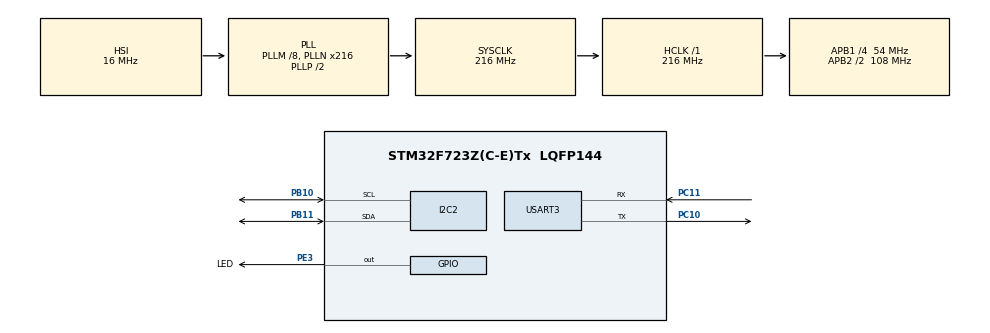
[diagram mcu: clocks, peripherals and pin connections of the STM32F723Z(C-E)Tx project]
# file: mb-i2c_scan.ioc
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FREERTOS.Tasks01=defaultTask,24,128,StartDefaultTask,Default,NULL,Dynamic,NULL,NULL;myTaskLED,8,128,StartTaskLED,Default,NULL,Dynamic,NULL,NULL
FREERTOS.configUSE_NEWLIB_REENTRANT=1
I2C2.Timing=0x20404768
Mcu.Family=STM32F7
Mcu.Name=STM32F723Z(C-E)Tx
Mcu.Package=LQFP144
NVIC.PriorityGroup=NVIC_PRIORITYGROUP_4
NVIC.TIM8_UP_TIM13_IRQn=true\:15\:0\:false\:false\:true\:false\:false\:true\:true
NVIC.TimeBase=TIM8_UP_TIM13_IRQn
NVIC.TimeBaseIP=TIM13
NVIC.USART3_IRQn=true\:5\:0\:false\:false\:true\:true\:true\:true\:true
PB10.Mode=I2C
PB10.Signal=I2C2_SCL
PB11.Mode=I2C
PB11.Signal=I2C2_SDA
PC10.Mode=Asynchronous
PC10.Signal=USART3_TX
PC11.Mode=Asynchronous
PC11.Signal=USART3_RX
PE3.GPIO_Label=LED
PE3.Signal=GPIO_Output
PH0-OSC_IN.Mode=HSE-External-Oscillator
PH0-OSC_IN.Signal=RCC_OSC_IN
PH1-OSC_OUT.Mode=HSE-External-Oscillator
PH1-OSC_OUT.Signal=RCC_OSC_OUT
ProjectManager.HeapSize=0x200
ProjectManager.StackSize=0x400
ProjectManager.TargetToolchain=STM32CubeIDE
RCC.AHBFreq_Value=216000000
RCC.APB1CLKDivider=RCC_HCLK_DIV4
RCC.APB1Freq_Value=54000000
RCC.APB1TimFreq_Value=108000000
RCC.APB2CLKDivider=RCC_HCLK_DIV2
RCC.APB2Freq_Value=108000000
RCC.APB2TimFreq_Value=216000000
RCC.CortexFreq_Value=216000000
RCC.HCLKFreq_Value=216000000
RCC.HSE_VALUE=24000000
RCC.HSI_VALUE=16000000
RCC.LSE_VALUE=32768
RCC.PLLM=8
RCC.PLLN=216
RCC.SYSCLKFreq_VALUE=216000000
RCC.SYSCLKSource=RCC_SYSCLKSOURCE_PLLCLK
RCC.USBFreq_Value=216000000
RCC.VCOOutputFreq_Value=432000000
USART3.VirtualMode-Asynchronous=VM_ASYNC
VP_FREERTOS_VS_CMSIS_V2.Mode=CMSIS_V2
VP_SYS_VS_tim13.Mode=TIM13
board=custom

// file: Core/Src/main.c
/* USER CODE BEGIN Header */
/**
 ******************************************************************************
 * @file           : main.c
 * @brief          : Main program body
 ******************************************************************************
 * @attention
 *
 * Copyright (c) 2022 STMicroelectronics.
 * All rights reserved.
 *
 * This software is licensed under terms that can be found in the LICENSE file
 * in the root directory of this software component.
 * If no LICENSE file comes with this software, it is provided AS-IS.
 *
 ******************************************************************************
 */
/* USER CODE END Header */
#include "main.h"
#include "cmsis_os.h"

/* USER CODE BEGIN Includes */
#include "serial.h"
#include "wire.h"
#include "led.h"
/* USER CODE END Includes */

I2C_HandleTypeDef hi2c2;

UART_HandleTypeDef huart3;

/* Definitions for defaultTask */
osThreadId_t defaultTaskHandle;
const osThreadAttr_t defaultTask_attributes = { .name = "defaultTask",
		.stack_size = 128 * 4, .priority = (osPriority_t) osPriorityNormal, };
/* Definitions for myTaskLED */
osThreadId_t myTaskLEDHandle;
const osThreadAttr_t myTaskLED_attributes = { .name = "myTaskLED", .stack_size =
		128 * 4, .priority = (osPriority_t) osPriorityLow, };

void SystemClock_Config(void);
static void MX_GPIO_Init(void);
static void MX_I2C2_Init(void);
static void MX_USART3_UART_Init(void);
void StartDefaultTask(void *argument);
void StartTaskLED(void *argument);

/* USER CODE BEGIN 0 */
byte flagLED = 0;
/* USER CODE END 0 */

int main(void) {

	/* MCU Configuration--------------------------------------------------------*/

	/* Reset of all peripherals, Initializes the Flash interface and the Systick. */
	HAL_Init();

	/* Configure the system clock */
	SystemClock_Config();

	/* Initialize all configured peripherals */
	MX_GPIO_Init();
	MX_I2C2_Init();
	MX_USART3_UART_Init();

	/* Init scheduler */
	osKernelInitialize();

	/* Create the thread(s) */
	/* creation of defaultTask */
	defaultTaskHandle = osThreadNew(StartDefaultTask, NULL,
			&defaultTask_attributes);

	/* creation of myTaskLED */
	myTaskLEDHandle = osThreadNew(StartTaskLED, NULL, &myTaskLED_attributes);

	/* Start scheduler */
	osKernelStart();

	/* We should never get here as control is now taken by the scheduler */
	/* Infinite loop */
	while (1) {

	}
}

void SystemClock_Config(void) {
	RCC_OscInitTypeDef RCC_OscInitStruct = { 0 };
	RCC_ClkInitTypeDef RCC_ClkInitStruct = { 0 };

	/** Configure the main internal regulator output voltage
	 */
	__HAL_RCC_PWR_CLK_ENABLE();
	__HAL_PWR_VOLTAGESCALING_CONFIG(PWR_REGULATOR_VOLTAGE_SCALE1);

	/** Initializes the RCC Oscillators according to the specified parameters
	 * in the RCC_OscInitTypeDef structure.
	 */
	RCC_OscInitStruct.OscillatorType = RCC_OSCILLATORTYPE_HSI;
	RCC_OscInitStruct.HSIState = RCC_HSI_ON;
	RCC_OscInitStruct.HSICalibrationValue = RCC_HSICALIBRATION_DEFAULT;
	RCC_OscInitStruct.PLL.PLLState = RCC_PLL_ON;
	RCC_OscInitStruct.PLL.PLLSource = RCC_PLLSOURCE_HSI;
	RCC_OscInitStruct.PLL.PLLM = 8;
	RCC_OscInitStruct.PLL.PLLN = 216;
	RCC_OscInitStruct.PLL.PLLP = RCC_PLLP_DIV2;
	RCC_OscInitStruct.PLL.PLLQ = 2;
	if (HAL_RCC_OscConfig(&RCC_OscInitStruct) != HAL_OK) {
		Error_Handler();
	}

	/** Activate the Over-Drive mode
	 */
	if (HAL_PWREx_EnableOverDrive() != HAL_OK) {
		Error_Handler();
	}

	/** Initializes the CPU, AHB and APB buses clocks
	 */
	RCC_ClkInitStruct.ClockType = RCC_CLOCKTYPE_HCLK | RCC_CLOCKTYPE_SYSCLK
			| RCC_CLOCKTYPE_PCLK1 | RCC_CLOCKTYPE_PCLK2;
	RCC_ClkInitStruct.SYSCLKSource = RCC_SYSCLKSOURCE_PLLCLK;
	RCC_ClkInitStruct.AHBCLKDivider = RCC_SYSCLK_DIV1;
	RCC_ClkInitStruct.APB1CLKDivider = RCC_HCLK_DIV4;
	RCC_ClkInitStruct.APB2CLKDivider = RCC_HCLK_DIV2;

	if (HAL_RCC_ClockConfig(&RCC_ClkInitStruct, FLASH_LATENCY_7) != HAL_OK) {
		Error_Handler();
	}
}

static void MX_I2C2_Init(void) {

	hi2c2.Instance = I2C2;
	hi2c2.Init.Timing = 0x20404768;
	hi2c2.Init.OwnAddress1 = 0;
	hi2c2.Init.AddressingMode = I2C_ADDRESSINGMODE_7BIT;
	hi2c2.Init.DualAddressMode = I2C_DUALADDRESS_DISABLE;
	hi2c2.Init.OwnAddress2 = 0;
	hi2c2.Init.OwnAddress2Masks = I2C_OA2_NOMASK;
	hi2c2.Init.GeneralCallMode = I2C_GENERALCALL_DISABLE;
	hi2c2.Init.NoStretchMode = I2C_NOSTRETCH_DISABLE;
	if (HAL_I2C_Init(&hi2c2) != HAL_OK) {
		Error_Handler();
	}

	/** Configure Analogue filter
	 */
	if (HAL_I2CEx_ConfigAnalogFilter(&hi2c2, I2C_ANALOGFILTER_ENABLE)
			!= HAL_OK) {
		Error_Handler();
	}

	/** Configure Digital filter
	 */
	if (HAL_I2CEx_ConfigDigitalFilter(&hi2c2, 0) != HAL_OK) {
		Error_Handler();
	}

}

static void MX_USART3_UART_Init(void) {

	huart3.Instance = USART3;
	huart3.Init.BaudRate = 115200;
	huart3.Init.WordLength = UART_WORDLENGTH_8B;
	huart3.Init.StopBits = UART_STOPBITS_1;
	huart3.Init.Parity = UART_PARITY_NONE;
	huart3.Init.Mode = UART_MODE_TX_RX;
	huart3.Init.HwFlowCtl = UART_HWCONTROL_NONE;
	huart3.Init.OverSampling = UART_OVERSAMPLING_16;
	huart3.Init.OneBitSampling = UART_ONE_BIT_SAMPLE_DISABLE;
	huart3.AdvancedInit.AdvFeatureInit = UART_ADVFEATURE_NO_INIT;
	if (HAL_UART_Init(&huart3) != HAL_OK) {
		Error_Handler();
	}

}

static void MX_GPIO_Init(void) {
	GPIO_InitTypeDef GPIO_InitStruct = { 0 };

	/* GPIO Ports Clock Enable */
	__HAL_RCC_GPIOE_CLK_ENABLE();
	__HAL_RCC_GPIOH_CLK_ENABLE();
	__HAL_RCC_GPIOB_CLK_ENABLE();
	__HAL_RCC_GPIOC_CLK_ENABLE();

	/*Configure GPIO pin Output Level */
	HAL_GPIO_WritePin(LED_GPIO_Port, LED_Pin, GPIO_PIN_RESET);

	/*Configure GPIO pin : LED_Pin */
	GPIO_InitStruct.Pin = LED_Pin;
	GPIO_InitStruct.Mode = GPIO_MODE_OUTPUT_PP;
	GPIO_InitStruct.Pull = GPIO_NOPULL;
	GPIO_InitStruct.Speed = GPIO_SPEED_FREQ_LOW;
	HAL_GPIO_Init(LED_GPIO_Port, &GPIO_InitStruct);

}

void StartDefaultTask(void *argument) {
	/* USER CODE BEGIN 5 */

	// scan for i2c devices
	i2cScan(&hi2c2,&huart3);

	/* Infinite loop */
	for (;;) {
		osDelay(100);
	}
	/* USER CODE END 5 */
}

void StartTaskLED(void *argument) {
	/* USER CODE BEGIN StartTaskLED */
	/* Infinite loop */
	for (;;) {
		if (flagLED) {
			toggleLED(250);
		}
		osDelay(1);
	}
	/* USER CODE END StartTaskLED */
}

void HAL_TIM_PeriodElapsedCallback(TIM_HandleTypeDef *htim) {
	if (htim->Instance == TIM13) {
		HAL_IncTick();
	}
}

void Error_Handler(void) {
	__disable_irq();
	while (1) {
	}
}
